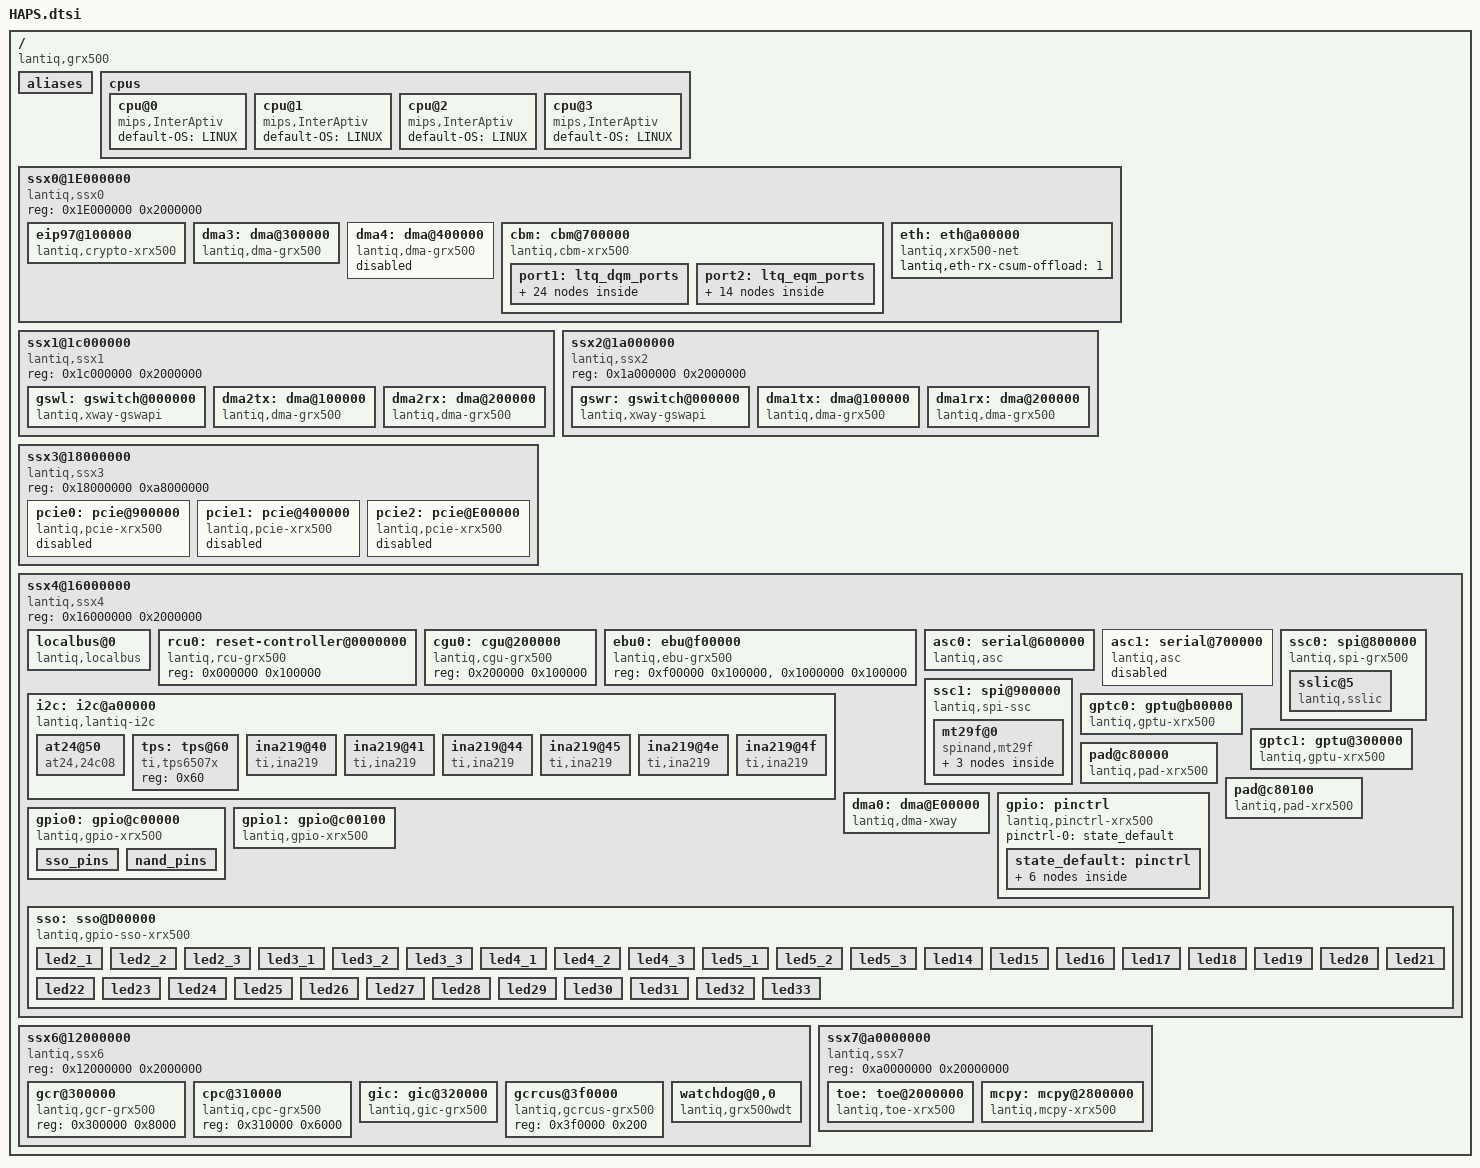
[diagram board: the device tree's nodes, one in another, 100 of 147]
/ {
	#address-cells = <1>;
	#size-cells = <1>;
	compatible = "lantiq,grx500","lantiq,xway";
	
	aliases {
		serial0 = &asc0;
		serial1 = &asc1;
		dma0    = &dma0;
		dma1    = &dma1tx;
		dma2    = &dma1rx;
		dma3    = &dma2tx;
		dma4    = &dma2rx;
		dma5    = &dma3;
		dma6    = &dma4;
		pcie0   = &pcie0;
		pcie1   = &pcie1;
		pcie2   = &pcie2;
		spi1 = &ssc1;
	};

	cpus {
		cpu@0 {
			compatible = "mips,InterAptiv";
			default-OS = "LINUX";
		};
		cpu@1 {
			compatible = "mips,InterAptiv";
			default-OS = "LINUX";
		};
		cpu@2 {
			compatible = "mips,InterAptiv";
			default-OS = "LINUX";
		};
		cpu@3 {
			compatible = "mips,InterAptiv";
			default-OS = "LINUX";
		};
	};

	ssx0@1E000000{
		#address-cells = <1>;
		#size-cells = <1>;
		compatible = "lantiq,ssx0", "simple-bus";
		reg = <0x1E000000 0x2000000>;
		ranges = <0x0 0x1E000000 0x02000000>;
		
		eip97@100000 {
			compatible = "lantiq,crypto-xrx500";
			reg = <0x100000 0x100000>;
			interrupt-parent = <&gic>;
			interrupts = <97 98 99>;
		};

		dma3: dma@300000 {
			compatible = "lantiq,dma-grx500";
			reg = <0x300000 0x100000>;
			interrupt-parent = <&gic>;
			interrupts = <77>;
			lantiq,dma-pkt-arb = <2>;
			lantiq,dma-burst = <16>;
			lantiq,dma-polling-cnt = <24>;
			lantiq,dma-chan-fc = <0>;
			lantiq,dma-desc-fod = <0>;
			lantiq,dma-desc-in-sram = <1>;
			lantiq,dma-drb = <0>;
			/*status = "disabled"; */
		};

		dma4: dma@400000 {
			compatible = "lantiq,dma-grx500";
			reg = <0x400000 0x100000>;
			interrupt-parent = <&gic>;
			interrupts = <78>;
			lantiq,dma-pkt-arb = <2>;
			lantiq,dma-burst = <16>;
			lantiq,dma-polling-cnt = <24>;
			lantiq,dma-chan-fc = <0>;
			lantiq,dma-desc-fod = <0>;
			lantiq,dma-desc-in-sram = <0>;
			lantiq,dma-drb = <0>;
			status = "disabled";
		};
		cbm: cbm@700000{
			compatible = "lantiq,cbm-xrx500";
			reg = < 0x700000 0x1000   /*TMU*/
				0x710000 0x10000 /*CBM*/
				0x720000 0x4000 /*QIDT*/
				0x730000 0x14000 /*SBIM*/
				0x750000 0x400 /*QEQCNTR*/
				0x750800 0x400 /*QDQCNTR*/
				0x760000 0x10000 /*LS*/
				0x780000 0x20000 /*CBM EQM*/
				0x7C0000 0x30000 /*CBM DQM*/
				0x800000 0x100000 /*FSQM0*/
				0x900000 0x100000 /*FSQM1*/
				0x500000 0x100000 /*CBM DMA DESC*/
				>;
				interrupt-parent = <&gic>;
				interrupts = <182 186 187 188 189>;
				port1: ltq_dqm_ports {
					DQ6 {
						lantiq,cbm-config = <6 16 2 1 1 2>;
					};
					DQ7 {
						lantiq,cbm-config = <7 17 2 2 1 2>;
					};
					DQ8 {
						lantiq,cbm-config = <8 18 2 3 1 2>;
					};
					DQ9 {
						lantiq,cbm-config = <9 19 2 4 1 2>;
					};
					DQ10 {
						lantiq,cbm-config = <10 20 2 5 1 2>;
					};
					DQ11 {
						lantiq,cbm-config = <11 21 2 6 1 2>;
					};
					DQ12 {
						lantiq,cbm-config = <12 22 2 9 1 2>;
					};
					DQ13 {
						lantiq,cbm-config = <13 23 2 10 1 2>;
					};
					DQ14 {
						lantiq,cbm-config = <14 24 2 11 1 2>;
					};
					DQ15 {
						lantiq,cbm-config = <15 25 2 12 1 2>;
					};
					DQ16 {
						lantiq,cbm-config = <16 26 2 13 1 2>;
					};
					DQ17 {
						lantiq,cbm-config = <17 27 2 14 1 2>;
					};
					DQ19 {
						lantiq,cbm-config = <19 28 1 15 1 2>;
					};
					DQ20 {
						lantiq,cbm-config = <20 29 1 5 1 2>;
					};
					DQ21 {
						lantiq,cbm-config = <21 30 1 6 1 2>;
					};
					DQ22 {
						lantiq,cbm-config = <22 41 1 11 1 2>;
					};
					DQ18 {
						lantiq,cbm-config = <18 0 1 13 1 2>;
					};
					DQ23 {
						lantiq,cbm-config = <23 31 255 255 1 2>;
					};
					DQ24 {
						lantiq,cbm-config = <24 38 255 255 1 32>;
					};
					DQ25 {
						lantiq,cbm-config = <25 39 255 255 1 32>;
					};
					DQ26 {
						lantiq,cbm-config = <26 40 255 255 1 32>;
					};
					DQ4 {
						lantiq,cbm-config = <4 32 255 255 1 32>;
					};
					DQ2 {
						lantiq,cbm-config = <2 35 255 255 2 1>;
					};
					/*DQ0 {
						lantiq,cbm-config = <0 33 255 255 3 1>;
					};*/
					DQ5 {
						lantiq,cbm-config = <5 37 255 255 1 2>;
					};
				};
			port2: ltq_eqm_ports {
					EQ1 {
						lantiq,cbm-config = <0 255 255 255 2 2>;
					};
					EQ2 {
						lantiq,cbm-config = <1 255 255 255 3 2>;
					};
					EQ3 {
						lantiq,cbm-config = <2 255 255 255 4 2>;
					};
					EQ4 {
						lantiq,cbm-config = <3 255 255 255 5 2>;
					};
					EQ5 {
						lantiq,cbm-config = <5 2 14 0 7 2>;
					};
					EQ5_1 {
						lantiq,cbm-config = <5 2 30 1 7 2>;
					};
					EQ6 {
						lantiq,cbm-config = <6 2 15 0 7 2>;
					};
					EQ6_1 {
						lantiq,cbm-config = <6 2 31 1 7 2>;
					};
					EQ7 {
						lantiq,cbm-config = <7 1 0 0 8 2>;
					};
					EQ7_1 {
						lantiq,cbm-config = <7 1 16 1 8 2>;
					};
					EQ8 {
						lantiq,cbm-config = <8 1 15 0 8 2>;
					};
					EQ8_1 {
						lantiq,cbm-config = <8 1 31 1 8 2>;
					};
					EQ9 {
						lantiq,cbm-config = <9 255 255 255 9 2>;
					};
					EQ15 {
						lantiq,cbm-config = <15 255 255 255 10 32>;
					};
			};
		};
		eth:eth@a00000{
			#address-cells = <1>;
			#size-cells = <0>;
			compatible = "lantiq,xrx500-net";
			lantiq,eth-rx-csum-offload = <1>;
		};
	};

	ssx1@1c000000 {
		#address-cells = <1>;
		#size-cells = <1>;
		compatible = "lantiq,ssx1", "simple-bus";
		reg = <0x1c000000 0x2000000>;
		ranges = <0x0 0x1c000000 0x02000000>;

		gswl: gswitch@000000 {
			compatible = "lantiq,xway-gswapi";
			reg = <0x000000 0x3000>;
			lantiq,gsw-devid = <0>;
		};

		dma2tx: dma@100000 {
			compatible = "lantiq,dma-grx500";
			reg = <0x100000 0x100000>;
			interrupt-parent = <&gic>;
			interrupts = <75>;
			lantiq,dma-pkt-arb = <2>;
			lantiq,dma-burst = <16>;
			lantiq,dma-polling-cnt = <24>;
			lantiq,dma-chan-fc = <1>;
			lantiq,dma-desc-fod = <1>;
			lantiq,dma-desc-in-sram = <0>;
			lantiq,dma-drb = <0>;
			/* status = "disabled"; */
		};

		dma2rx: dma@200000 {
			compatible = "lantiq,dma-grx500";
			reg = <0x200000 0x100000>;
			interrupt-parent = <&gic>;
			interrupts = <76>;
			lantiq,dma-pkt-arb = <2>;
			lantiq,dma-burst = <16>;
			lantiq,dma-polling-cnt = <24>;
			lantiq,dma-chan-fc = <0>;
			lantiq,dma-desc-fod = <1>;
			lantiq,dma-desc-in-sram = <0>;
			lantiq,dma-drb = <0>;
			/* status = "disabled"; */
		};
	};

	ssx2@1a000000 {
		#address-cells = <1>;
		#size-cells = <1>;
		compatible = "lantiq,ssx2", "simple-bus";
		reg = <0x1a000000 0x2000000>;
		ranges = <0x0 0x1a000000 0x02000000>;

		gswr: gswitch@000000 {
			compatible = "lantiq,xway-gswapi";
			reg = <0x000000 0x3000>;
			lantiq,gsw-devid = <1>;
		};

		dma1tx: dma@100000 {
			compatible = "lantiq,dma-grx500";
			reg = <0x100000 0x100000>;
			interrupt-parent = <&gic>;
			interrupts = <73>;
			lantiq,dma-pkt-arb = <2>;
			lantiq,dma-burst = <16>;
			lantiq,dma-polling-cnt = <24>;
			lantiq,dma-chan-fc = <1>;
			lantiq,dma-desc-fod = <1>;
			lantiq,dma-desc-in-sram = <0>;
			lantiq,dma-drb = <0>;
		};

		dma1rx: dma@200000 {
			compatible = "lantiq,dma-grx500";
			reg = <0x200000 0x100000>;
			interrupt-parent = <&gic>;
			interrupts = <74>;
			lantiq,dma-pkt-arb = <2>;
			lantiq,dma-burst = <16>;
			lantiq,dma-polling-cnt = <24>;
			lantiq,dma-chan-fc = <0>;
			lantiq,dma-desc-fod = <1>;
			lantiq,dma-desc-in-sram = <0>;
			lantiq,dma-drb = <0>;
		};
	};

	ssx3@18000000 {
		#address-cells = <1>;
		#size-cells = <1>;
		compatible = "lantiq,ssx3", "simple-bus";
		reg = <0x18000000 0xa8000000>;
		ranges = <0x0 0x18000000 0xa8000000>;

		pcie0:pcie@900000 {
			status = "disabled";
			compatible = "lantiq,pcie-xrx500";
			device_type = "pci";
			#address-cells = <3>;
			#size-cells = <2>;
			reg = < 
				0x900000 0x100000 /* RC controller */
				0xA3000000 0x800000 /* Cfg*/
				0x800000 0x100000 /* App logic */
				0x500000 0x100000 /* PCIe PHY Reg */
				0x600000 0x100000 /* MSI addr space */
				0x700000 0x100000 /* MSI PIC */
			>;
			reg-names = "csr", "cfg", "app", "phy", "msi", "pic";
			interrupt-parent = <&gic>;
			interrupts = <136 137 138 139 140 141 142 143 160>;
			interrupt-names = "msi0", "msi1", "msi2", "msi3", "msi4", "msi5", "msi6", "msi7", "ir";
			#interrupt-cells = <1>;
			interrupt-map-mask = <0 0 0 0x7>;
			interrupt-map = <0 0 0 1 &gic  144>,
					<0 0 0 2 &gic  145>,
					<0 0 0 3 &gic  146>,
					<0 0 0 4 &gic  147>;
			ranges = <0x02000000 0 0xa0000000 0xa0000000 0 0x03000000    /* Non-pretechable memory 32bit */
				  0x01000000 0 0xa3800000 0xa3800000 0 0x00100000    /* Downsream I/O */ 
				 >;

			resets = <&rcu0 12>; 
			reset-names = "phy";
			lantiq,inbound-shift = <5>;
			lantiq,outbound-shift = <4>;
			lantiq,clkout = <22>;
		};

		pcie1:pcie@400000 {
			status = "disabled";
			compatible = "lantiq,pcie-xrx500";
			device_type = "pci";
			#address-cells = <3>;
			#size-cells = <2>;
			reg = <
				0x400000 0x100000 /* RC controller */
				0x9f000000 0x800000 /* Cfg*/
				0x300000 0x100000 /* App logic */
				0x000000 0x100000 /* PCIe PHY Reg */
				0x100000 0x100000 /* MSI phy space */
				0x200000 0x100000 /* MSI PIC */
				
			>;
			reg-names = "csr", "cfg", "app", "phy", "msi", "pic";
			interrupt-parent = <&gic>;
			interrupts = <45 46 47 48 49 50 51 52 57>;
			interrupt-names = "msi0", "msi1", "msi2", "msi3", "msi4", "msi5", "msi6", "msi7", "ir";
			#interrupt-cells = <1>;
			interrupt-map-mask = <0 0 0 0x7>;
			interrupt-map = <0 0 0 1 &gic  17>,
					<0 0 0 2 &gic  18>,
					<0 0 0 3 &gic  19>,
					<0 0 0 4 &gic  20>;
			ranges = < 0x02000000 0 0x9c000000 0x9c000000 0 0x03000000    /* Non-pretechable memory 32bit */
				   0x01000000 0 0x9f800000 0x9f800000 0 0x00100000    /* Downsream I/O */ 
				 >;
						
			resets = <&rcu0 13>; 
			reset-names = "phy";
			lantiq,inbound-shift = <9>;
			lantiq,outbound-shift = <8>;
			lantiq,clkout = <23>;
		};

		pcie2:pcie@E00000 {
			status = "disabled";
			compatible = "lantiq,pcie-xrx500";
			#address-cells = <3>;
			#size-cells = <2>;
			device_type = "pci";
			reg = <
				0xe00000 0x100000 /* RC controller */
				0xa7000000 0x800000 /* Cfg*/
				0xd00000 0x100000 /* App logic */
				0xa00000 0x100000 /* PCIe PHY Reg */
				0xb00000 0x100000 /* MSI addr space */
				0xc00000 0x100000 /* MSI PIC */
			>;
			reg-names = "csr", "cfg", "app", "phy", "msi", "pic";
			interrupt-parent = <&gic>;
			interrupts = <32 33 34 35 36 37 38 39 63>;
			interrupt-names = "msi0", "msi1", "msi2", "msi3", "msi4", "msi5", "msi6", "msi7", "ir";
			#interrupt-cells = <1>;
			interrupt-map-mask = <0 0 0 0x7>;
			interrupt-map = <0 0 0 1 &gic  163>,
					<0 0 0 2 &gic  164>,
					<0 0 0 3 &gic  165>,
					<0 0 0 4 &gic  166>;
			ranges = < 0x02000000 0 0xa4000000 0xa4000000 0 0x03000000    /* Non-pretechable memory 32bit */
				   0x01000000 0 0xa7800000 0xa7800000 0 0x00100000    /* Downsream I/O */ 
				 >;
			resets = <&rcu0 10>; 
			reset-names = "phy";
			lantiq,inbound-shift = <13>;
			lantiq,outbound-shift = <12>;
			lantiq,clkout = <24>;
		};
	};

	ssx4@16000000 {
		#address-cells = <1>;
		#size-cells = <1>;
		compatible = "lantiq,ssx4", "simple-bus";
		reg = <0x16000000 0x2000000>;
		ranges = <0x0 0x16000000 0x02000000>;

		localbus@0 {
			#address-cells = <2>;
			#size-cells = <1>;
			ranges = <0 0 0x1400000 0xc00000 /* addrsel0 */
			1 0 0x1c00000 0x100000>; /* addsel1 */
			compatible = "lantiq,localbus", "simple-bus";
		};

		rcu0: reset-controller@0000000 {
			compatible = "lantiq,rcu-grx500";
			reg = <0x000000 0x100000>;
			#reset-cells = <1>; 
		};

		cgu0: cgu@200000 {
			compatible = "lantiq,cgu-grx500";
			reg = <0x200000 0x100000>;
		};

		ebu0: ebu@f00000 {
			compatible = "lantiq,ebu-grx500";
			reg = <0xf00000 0x100000>,
				<0x1000000 0x100000>; 
			reg-names = "ebunand_reg", "hsnand_reg";
		};

		asc0: serial@600000 {
			compatible = "lantiq,asc";
			reg = <0x600000 0x100000>;
			interrupt-parent = <&gic>;
			interrupts = <111 113 114>;
		};

		asc1: serial@700000 {
			compatible = "lantiq,asc";
			reg = <0x700000 0x100000>;
			interrupt-parent = <&gic>;
			interrupts = <84 86 87>;
			status = "disabled";
		};

		ssc0: spi@800000 {
			compatible = "lantiq,spi-grx500";
			reg = <0x800000 0x400>;
			interrupt-parent = <&gic>;
			interrupts = <22 23 24>;
			#address-cells = <1>;
			#size-cells = <0>;

			sslic@5 {
				compatible = "lantiq,sslic";
				spi-max-frequency = <8000000>;
				reg = <5>;
				interrupts = <217>;
				interrupt-parent = <&gic>;
			};
		};

		ssc1: spi@900000 {
			compatible = "lantiq,spi-ssc";
			reg = <0x900000 0x400>;
			interrupt-parent = <&gic>;
			interrupts = <107 108 109>;
			#address-cells = <1>;
			#size-cells = <1>;
			lantiq,ssc-port = <1>;
			mt29f@0 {
				#address-cells = <1>;
				#size-cells = <1>;
				reg = <0 1>;
				compatible = "spinand,mt29f";
				linux,modalias = "mt29f";
				spi-max-frequency = <1000000>;

				partition@0 {
					label = "uboot";
					reg = <0x000000 0x100000>;
				};

				partition@100000 {
					label = "data";
					reg = <0x100000 0x1000000>;
				};	
				
				partition@1100000 {
					label = "res";
					reg = <0x1100000 0x6E00000>;
				};
			};
		};

		i2c: i2c@a00000 {
                	#address-cells = <1>;
                	#size-cells = <0>;
			status = "okay";
			compatible = "lantiq,lantiq-i2c";
			clock-frequency = <100000>;
			reg = <0xa00000 0x10000>;
			interrupt-parent = <&gic>;
			interrupts = <41 40 31 44>;

                        at24@50 {
				compatible = "at24,24c08";
				pagesize = <32>;
				reg = <0x50>;
			};

                        tps: tps@60 {
			        compatible = "ti,tps6507x";
                                reg = <0x60>;
                        };

			ina219@40 {
        			compatible = "ti,ina219";
        			reg = <0x40>;
        			shunt-resistor = <1000>;
			};
                        ina219@41 {
                                compatible = "ti,ina219";
                                reg = <0x41>;
                                shunt-resistor = <1000>;
                        };
                        ina219@44 {
                                compatible = "ti,ina219";
                                reg = <0x44>;
                                shunt-resistor = <1000>;
                        };
                        ina219@45 {
                                compatible = "ti,ina219";
                                reg = <0x45>;
                                shunt-resistor = <1000>;
                        };
                        ina219@4e {
                                compatible = "ti,ina219";
                                reg = <0x4e>;
                                shunt-resistor = <1000>;
                        };
                        ina219@4f {
                                compatible = "ti,ina219";
                                reg = <0x4f>;
                                shunt-resistor = <1000>;
                        };
		};

		gptc0: gptu@b00000 {
			compatible = "lantiq,gptu-xrx500";
			reg = <0xb00000 0x400>;
			interrupt-parent = <&gic>;
			interrupts = <126 127 128 129 130 131>;
		};

		gptc1: gptu@300000 {
			compatible = "lantiq,gptu-xrx500";
			reg = <0x300000 0x400>;
			interrupt-parent = <&gic>;
			interrupts = <168 169 170 171 172 173>;
		};

		pad@c80000{
			compatible = "lantiq,pad-xrx500";
			lantiq,bank = <0>;
			reg = <0xc80000 0x100>;
		};

		pad@c80100{
			compatible = "lantiq,pad-xrx500";
			lantiq,bank = <1>;
			reg = <0xc80100 0x100>;
		};

		dma0: dma@E00000 {
			compatible = "lantiq,dma-xway","lantiq,dma0-grx500";
			reg = <0xE00000 0x100000>;
			interrupt-parent = <&gic>;
			interrupts = <72>;
			lantiq,desc-num = <16>;
			lantiq,dma-burst = <2>;
			lantiq,dma-polling-cnt = <4>;
			lantiq,dma-drb = <1>;
		};

		gpio: pinctrl {
			compatible = "lantiq,pinctrl-xrx500";
			pinctrl-names = "default";
			pinctrl-0 = <&state_default>;


			state_default: pinctrl {
				ledc {
					lantiq,groups = "ledc";
					lantiq,function = "ledc";
				};
				i2c {
					lantiq,groups = "i2c";
					lantiq,function = "i2c";
				};
				spi0 {
					lantiq,groups = "spi0", "spi0_cs1";
					lantiq,function = "spi0";
				};
				spi1 {
					lantiq,groups = "spi1", "spi1_cs0";
					lantiq,function = "spi1";
				};

				nand {
					lantiq,groups = "nand cle", "nand ale", 
						"nand rd", "nand rdy",
						"nand d0", "nand d1",
						"nand d2", "nand d3",
						"nand d4", "nand d5",
						"nand d6", "nand d7",
						"nand cs1", "nand wr",
						"nand wp", "nand se";
					lantiq,function = "ebu";   
				};
                                conf{
                                        lantiq,pins = "io21", "io22";
                                        lantiq,open-drain=<1>;
                                };
			};
		};

		gpio0: gpio@c00000 {
			compatible = "lantiq,gpio-xrx500";
			gpio-controller;
			#gpio-cells = <2>;
			reg = <0xc00000 0x80>;
			lantiq,bank = <0>;
			sso_pins: sso_pins {
				hog-as-output;
				gpio = <4 5 6>;
			};
			nand_pins: nand_pins {
				hog-as-output;
				gpio = <24 13 49 50 51 52 53 54 55 56 57 23 59 60 61>;
			};
		};

		gpio1: gpio@c00100 {
			compatible = "lantiq,gpio-xrx500";
			gpio-controller;
			#gpio-cells = <2>;
			reg = <0xc00100 0x80>;
			lantiq,bank = <1>;
		};

		sso: sso@D00000 {
			compatible = "lantiq,gpio-sso-xrx500";
			reg = <0xD00000 0x2CC>;
			#gpio-cells = <2>;
			gpio-controller;

			lantiq,groups = <0xf>;
			/* lantiq,phy1 = <0x7>; */
			/* lantiq,phy2 = <0x7>; */
			/* lantiq,rising; */
			#address-cells = <1>;
			#size-cells = <0>;
			led2_1 {
				label = "led2_1";
				reg = <0x0>;
			};
			led2_2 {
				label = "led2_2";
				reg = <0x1>;
			};
			led2_3 {
				label = "led2_3";
				reg = <0x2>;
			};
			led3_1 {
				label = "led3_1";
				reg = <0x3>;
			};
			led3_2 {
				label = "led3_2";
				reg = <0x4>;
			};
			led3_3 {
				label = "led3_3";
				reg = <0x5>;
			};
			led4_1 {
				label = "led4_1";
				reg = <0x6>;
			};
			led4_2 {
				label = "led4_2";
				reg = <0x7>;
			};
			led4_3 {
				label = "led4_3";
				reg = <0x8>;
			};
			led5_1 {
				label = "led5_1";
				reg = <0x9>;
			};
			led5_2 {
				label = "led5_2";
				reg = <0xa>;
			};
			led5_3 {
				label = "led5_3";
				reg = <0xb>;
			};
			led14 {
				label = "led14";
				reg = <0xc>;
			};
			led15 {
				label = "led15";
				reg = <0xd>;
			};
			led16 {
				label = "led16";
				reg = <0xe>;
			};
			led17 {
				label = "led17";
				reg = <0xf>;
			};
			led18 {
				label = "led18";
				reg = <0x10>;
			};
			led19 {
				label = "led19";
				reg = <0x11>;
			};
			led20 {
				label = "led20";
				reg = <0x12>;
			};
			led21 {
				label = "led21";
				reg = <0x13>;
			};
			led22 {
				label = "led22";
				reg = <0x14>;
			};
			led23 {
				label = "led23";
				reg = <0x15>;
			};
			led24 {
				label = "led24";
				reg = <0x16>;
			};
			led25 {
				label = "led25";
				reg = <0x17>;
			};
			led26 {
				label = "led26";
				reg = <0x18>;
			};
			led27 {
				label = "led27";
				reg = <0x19>;
			};
			led28 {
				label = "led28";
				reg = <0x1a>;
			};
			led29 {
				label = "led29";
				reg = <0x1b>;
			};
			led30 {
				label = "led30";
				reg = <0x1c>;
			};
			led31 {
				label = "led31";
				reg = <0x1d>;
			};
			led32 {
				label = "led32";
				reg = <0x1e>;
			};
			led33 {
				label = "led33";
				reg = <0x1f>;
			};
		};
	};

	ssx6@12000000 {
		#address-cells = <1>;
		#size-cells = <1>;
		compatible = "lantiq,ssx6", "simple-bus";
		reg = <0x12000000 0x2000000>;
		ranges = <0x0 0x12000000 0x02000000>;

		gcr@300000 {
			compatible = "lantiq,gcr-grx500";
			reg = <0x300000 0x8000>;
		};

		cpc@310000 {
			compatible = "lantiq,cpc-grx500";
			reg = <0x310000 0x6000>;
		};
	
		gic: gic@320000 {
			#interrupt-cells = <1>;
			interrupt-controller;
			compatible = "lantiq,gic-grx500";
			reg = <0x320000 0x20000>;
		};
		
		gcrcus@3f0000 {
			compatible = "lantiq,gcrcus-grx500";
			reg = <0x3f0000 0x200>;
		};

		watchdog@0,0 {
			#interrupt-cells = <1>;
			compatible = "lantiq,grx500wdt";
			reg = <0 0>;
			interrupt-parent = <&gic>;
			interrupts = <264>;
			timeout-sec = <60>;
		};
	};

	ssx7@a0000000 {
		#address-cells = <1>;
		#size-cells = <1>;
		compatible = "lantiq,ssx7", "simple-bus";
		reg = <0xa0000000 0x20000000>;
		ranges = <0x0 0xa0000000 0x20000000>;

		toe: toe@2000000 {
			#address-cells = <1>;
			#size-cells = <1>;
			compatible = "lantiq,toe-xrx500";
			reg = <0x2000000 0x10000
				   0x2013000 0x4000>;
			interrupt-parent = <&gic>;
			interrupts = <79 80 81 82 83 190 191 192 193 194 195 196 197 198 199>;
		};

		mcpy: mcpy@2800000 {
			#address-cells = <1>;
			#size-cells = <1>;
			compatible = "lantiq,mcpy-xrx500";
			reg = <0x2800000 0x800000>;
			interrupt-parent = <&gic>;
            interrupts = <200 201 202 203 204 205 206 207 208 209 210 211 212 213 214 215 216>;
            interrupt-names = "yld0", "yld1", "yld2", "yld3", "yld4", "yld5", "yld6", "yld7", "irq0", "irq1", "irq2", "irq3", "irq4", "irq5", "irq6", "irq7";
            /* Prio (1 is high), reserved for which VPE. (-1 NO reserve), trank size, irq_interval,  Enable (1 is En) */
            /* Trunk size:  -1 - Default Value, 0-"512B", 1-"1KB", 2-"2KB", 3-"4KB", 4-"8KB", 5-"16KB", 6-"32KB", 7-"64KB" */
            /* IRQ interval: 0 - Default Value> */
            /* mcpy ch id from 0 to 7, default setting please refer to the mcpy driver source code */
            /* lantiq,mcpy-ch0 = <1 0 -1 0 1>;  set mcpy ch0 to high prio, reserved for vpe 0, defaut trunk size, default irq_interval, enable*/
            lantiq,mcpy-minlen = <64>;
            lantiq,umt0-dmacid = <7>;
            lantiq,umt1-dmacid = <8>;
            lantiq,umt2-dmacid = <9>;
            lantiq,umt3-dmacid = <10>;
		}; 
	};	
	
};
